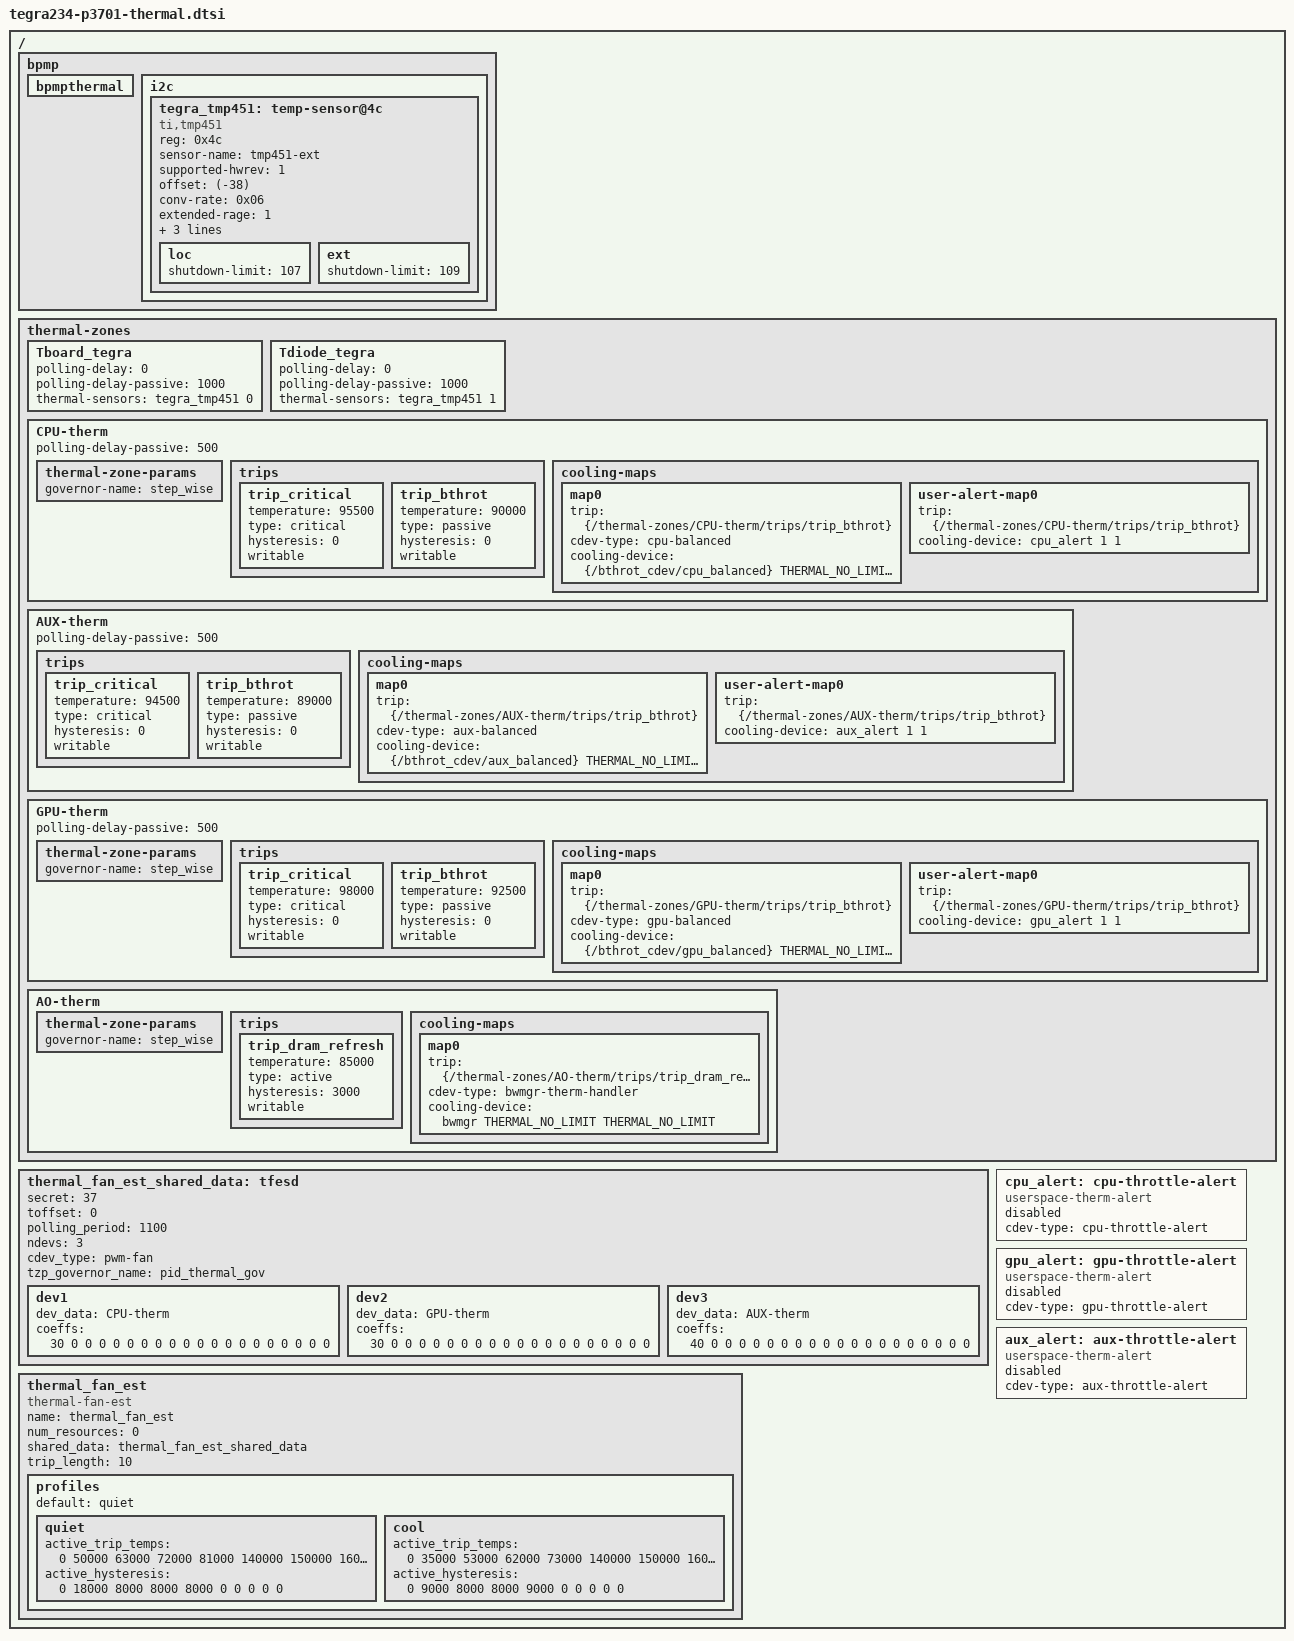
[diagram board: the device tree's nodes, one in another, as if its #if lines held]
/*
 * Copyright (c) 2021, NVIDIA CORPORATION.  All rights reserved.
 *
 * This program is free software; you can redistribute it and/or modify it
 * under the terms and conditions of the GNU General Public License,
 * version 2, as published by the Free Software Foundation.
 *
 * This program is distributed in the hope it will be useful, but WITHOUT
 * ANY WARRANTY; without even the implied warranty of MERCHANTABILITY or
 * FITNESS FOR A PARTICULAR PURPOSE.  See the GNU General Public License for
 * more details.
 *
 * You should have received a copy of the GNU General Public License
 * along with this program.  If not, see <http://www.gnu.org/licenses/>.
 */

#include <dt-bindings/interrupt-controller/arm-gic.h>
#include <dt-bindings/gpio/tegra234-gpio.h>
#include <dt-bindings/thermal/thermal.h>
#include "tegra234-balanced-throttle.dtsi"

/* THERMAL gpio definitions */
#define TEMP_ALERT TEGRA234_MAIN_GPIO(H, 2)

/ {
	bpmp {
		bpmpthermal {
			status = "okay";
		};
	};

#if TEGRA_BPMP_FW_DT_VERSION >= DT_VERSION_2
	bpmp { i2c {
#else
	bpmp_i2c {
#endif
		tegra_tmp451: temp-sensor@4c {
			status = "okay";
			#thermal-sensor-cells = <1>;
			compatible = "ti,tmp451";
			reg = <0x4c>;
			sensor-name = "tmp451-ext";
			supported-hwrev = <1>;
			offset = <(-38)>;
			conv-rate = <0x06>;
			extended-rage = <1>;

			interrupt-parent = <&tegra_main_gpio>;
			interrupts = <TEMP_ALERT IRQ_TYPE_LEVEL_LOW>;
			temp-alert-gpio = <&tegra_main_gpio TEMP_ALERT 0>;

			/* vdd-supply configured in power tree */

			loc {
				/* set to maximum for not having local  shutdown */
				shutdown-limit = <107>;
			};
			ext {
				shutdown-limit = <109>;
			};
		};
#if TEGRA_BPMP_FW_DT_VERSION >= DT_VERSION_2
	}; };
#else
	};
#endif

	thermal-zones {
		status = "okay";

		Tboard_tegra: Tboard_tegra {
			status = "okay";
			polling-delay = <0>;
			polling-delay-passive = <1000>;
			thermal-sensors = <&tegra_tmp451 0>;
		};

		Tdiode_tegra: Tdiode_tegra {
			status = "okay";
			polling-delay = <0>;
			polling-delay-passive = <1000>;
			thermal-sensors = <&tegra_tmp451 1>;
		};
		CPU-therm {
			status = "okay";
			polling-delay-passive = <500>;

			thermal-zone-params {
				governor-name = "step_wise";
			};

			trips {
				trip_critical {
					temperature = <95500>;
					type = "critical";
					hysteresis = <0>;
					writable;
				};
				trip_bthrot {
					temperature = <90000>;
					type = "passive";
					hysteresis = <0>;
					writable;
				};
			};
			cooling-maps {
				map0 {
					trip = <&{/thermal-zones/CPU-therm/trips/trip_bthrot}>;
					cdev-type = "cpu-balanced";
					cooling-device = <&{/bthrot_cdev/cpu_balanced} THERMAL_NO_LIMIT THERMAL_NO_LIMIT>;
				};
			};
		};

		AUX-therm {
			status = "okay";
			polling-delay-passive = <500>;
			trips {
				trip_critical {
					temperature = <94500>;
					type = "critical";
					hysteresis = <0>;
					writable;
				};

				trip_bthrot {
					temperature = <89000>;
					type = "passive";
					hysteresis = <0>;
					writable;
				};
			};
			cooling-maps {
				map0 {
					trip = <&{/thermal-zones/AUX-therm/trips/trip_bthrot}>;
					cdev-type = "aux-balanced";
					cooling-device = <&{/bthrot_cdev/aux_balanced} THERMAL_NO_LIMIT THERMAL_NO_LIMIT>;
				};
			};
		};

		GPU-therm {
			status = "okay";
			polling-delay-passive = <500>;

			thermal-zone-params {
				governor-name = "step_wise";
			};

			trips {
				trip_critical {
					temperature = <98000>;
					type = "critical";
					hysteresis = <0>;
					writable;
				};
				trip_bthrot {
					temperature = <92500>;
					type = "passive";
					hysteresis = <0>;
					writable;
				};
			};
			cooling-maps {
				map0 {
					trip = <&{/thermal-zones/GPU-therm/trips/trip_bthrot}>;
					cdev-type = "gpu-balanced";
					cooling-device = <&{/bthrot_cdev/gpu_balanced} THERMAL_NO_LIMIT THERMAL_NO_LIMIT>;
				};
			};

		};

		AO-therm {
			status = "okay";

			thermal-zone-params {
				governor-name = "step_wise";
			};

			trips {
				trip_dram_refresh {
					temperature = <85000>;
					type = "active";
					hysteresis = <3000>;
					writable;
				};
			};
			cooling-maps {
				map0 {
					trip = <&{/thermal-zones/AO-therm/trips/trip_dram_refresh}>;
					cdev-type = "bwmgr-therm-handler";
					cooling-device = <&bwmgr THERMAL_NO_LIMIT THERMAL_NO_LIMIT>;
				};
			};
		};
	};

	thermal_fan_est_shared_data: tfesd {
		secret = <37>;
		toffset = <0>;
		polling_period = <1100>;
		ndevs = <3>;
		cdev_type = "pwm-fan";
		tzp_governor_name = "pid_thermal_gov";

		dev1 {
			dev_data = "CPU-therm";
			coeffs = <30 0 0 0 0 0 0 0 0 0 0 0 0 0 0 0 0 0 0 0>;
		};
		dev2 {
			dev_data = "GPU-therm";
			coeffs = <30 0 0 0 0 0 0 0 0 0 0 0 0 0 0 0 0 0 0 0>;
		};
		dev3 {
			dev_data = "AUX-therm";
			coeffs = <40 0 0 0 0 0 0 0 0 0 0 0 0 0 0 0 0 0 0 0>;
		};
	};

	thermal_fan_est {
		compatible = "thermal-fan-est";
		name = "thermal_fan_est";
		status = "okay";
		num_resources = <0>;
		shared_data = <&thermal_fan_est_shared_data>;
		trip_length = <10>;
		profiles {
			default = "quiet";
			quiet {
				active_trip_temps = <0 50000 63000 72000 81000
						140000 150000 160000 170000 180000>;
				active_hysteresis = <0 18000 8000 8000 8000
						0 0 0 0 0>;
			};
			cool {
				active_trip_temps = <0 35000 53000 62000 73000
						140000 150000 160000 170000 180000>;
				active_hysteresis = <0 9000 8000 8000 9000
						0 0 0 0 0>;
			};
		};
	};

	cpu_alert: cpu-throttle-alert {
		compatible = "userspace-therm-alert";
		cdev-type = "cpu-throttle-alert";
		status = "disabled";
		#cooling-cells = <2>;
	};

	gpu_alert: gpu-throttle-alert {
		compatible = "userspace-therm-alert";
		cdev-type = "gpu-throttle-alert";
		status = "disabled";
		#cooling-cells = <2>;
	};

	aux_alert: aux-throttle-alert {
		compatible = "userspace-therm-alert";
		cdev-type = "aux-throttle-alert";
		status = "disabled";
		#cooling-cells = <2>;
	};

	thermal-zones {
		CPU-therm {
			cooling-maps {
				user-alert-map0 {
					trip = <&{/thermal-zones/CPU-therm/trips/trip_bthrot}>;
					cooling-device = <&cpu_alert 1 1>;
				};
			};
		};
		AUX-therm {
			cooling-maps {
				user-alert-map0 {
					trip = <&{/thermal-zones/AUX-therm/trips/trip_bthrot}>;
					cooling-device = <&aux_alert 1 1>;
				};
			};
		};
		GPU-therm {
			cooling-maps {
				user-alert-map0 {
					trip = <&{/thermal-zones/GPU-therm/trips/trip_bthrot}>;
					cooling-device = <&gpu_alert 1 1>;
				};
			};
		};
	};
};
